VERSION ""

NS_ :

BS_:

BU_:
VAL_TABLE_ WarnLevel 2 "Level 2" 1 "Level 1" 0 "NoWarn" ;
VAL_TABLE_ LCAWarn 1 "CVW" 0 "BSD" ;
VAL_TABLE_ Status 1 "abnormal" 0 "Normal" ;
VAL_TABLE_ Lock 2 "RemoteControlLock" 1 "InteriorLock" 0 "UnLock" ;
VAL_TABLE_ Brake 1 "Brake" 0 " Normal" ;
VAL_TABLE_ Switch 1 "ON" 0 "OFF" ;
VAL_TABLE_ Gear 3 "D" 2 "N" 1 "R" 0 "P" ;

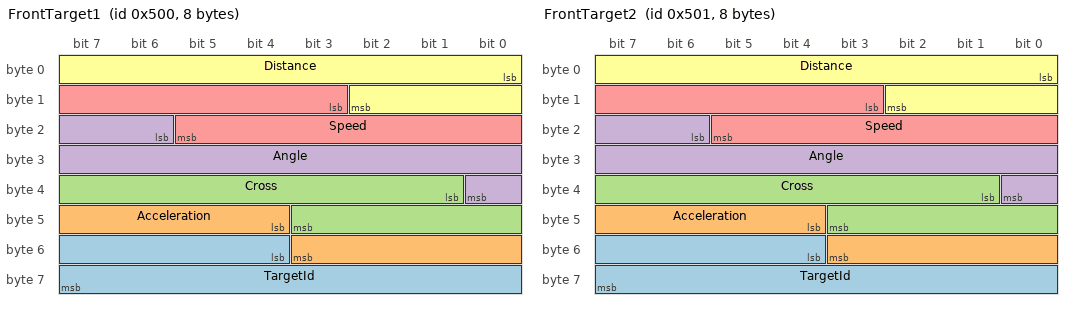
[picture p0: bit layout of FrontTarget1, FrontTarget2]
BO_ 1280 FrontTarget1: 8 Vector__XXX
 SG_ TargetId : 52|12@1+ (1,0) [0|0] "" Vector__XXX
 SG_ Acceleration : 44|8@1- (0.1,0) [0|0] "m/s^2" Vector__XXX
 SG_ Cross : 33|11@1- (0.1,0) [0|0] "m" Vector__XXX
 SG_ Angle : 22|11@1- (0.1,0) [0|0] "deg" Vector__XXX
 SG_ Speed : 11|11@1- (0.1,0) [0|0] "m/s" Vector__XXX
 SG_ Distance : 0|11@1+ (0.1,0) [0|0] "m" Vector__XXX

BO_ 1281 FrontTarget2: 8 Vector__XXX
 SG_ TargetId : 52|12@1+ (1,0) [0|0] "" Vector__XXX
 SG_ Acceleration : 44|8@1- (0.1,0) [0|0] "m/s^2" Vector__XXX
 SG_ Cross : 33|11@1- (0.1,0) [0|0] "m" Vector__XXX
 SG_ Angle : 22|11@1- (0.1,0) [0|0] "deg" Vector__XXX
 SG_ Speed : 11|11@1- (0.1,0) [0|0] "m/s" Vector__XXX
 SG_ Distance : 0|11@1+ (0.1,0) [0|0] "m" Vector__XXX

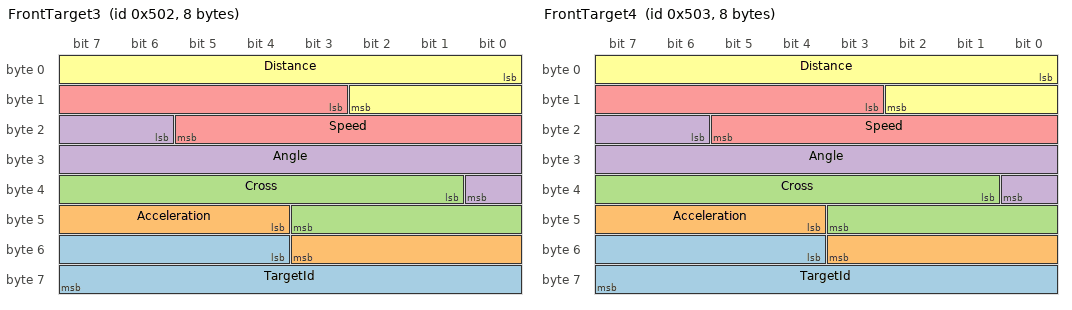
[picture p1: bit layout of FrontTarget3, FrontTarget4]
BO_ 1282 FrontTarget3: 8 Vector__XXX
 SG_ TargetId : 52|12@1+ (1,0) [0|0] "" Vector__XXX
 SG_ Acceleration : 44|8@1- (0.1,0) [0|0] "m/s^2" Vector__XXX
 SG_ Cross : 33|11@1- (0.1,0) [0|0] "m" Vector__XXX
 SG_ Angle : 22|11@1- (0.1,0) [0|0] "deg" Vector__XXX
 SG_ Speed : 11|11@1- (0.1,0) [0|0] "m/s" Vector__XXX
 SG_ Distance : 0|11@1+ (0.1,0) [0|0] "m" Vector__XXX

BO_ 1283 FrontTarget4: 8 Vector__XXX
 SG_ TargetId : 52|12@1+ (1,0) [0|0] "" Vector__XXX
 SG_ Acceleration : 44|8@1- (0.1,0) [0|0] "m/s^2" Vector__XXX
 SG_ Cross : 33|11@1- (0.1,0) [0|0] "m" Vector__XXX
 SG_ Angle : 22|11@1- (0.1,0) [0|0] "deg" Vector__XXX
 SG_ Speed : 11|11@1- (0.1,0) [0|0] "m/s" Vector__XXX
 SG_ Distance : 0|11@1+ (0.1,0) [0|0] "m" Vector__XXX

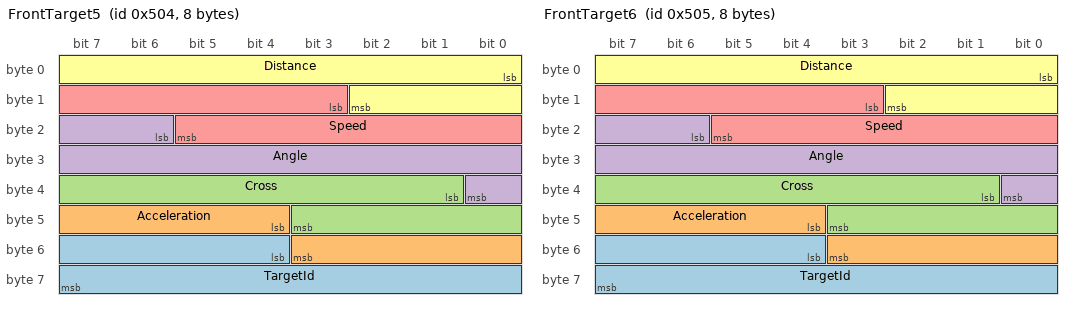
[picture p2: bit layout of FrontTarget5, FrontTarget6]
BO_ 1284 FrontTarget5: 8 Vector__XXX
 SG_ TargetId : 52|12@1+ (1,0) [0|0] "" Vector__XXX
 SG_ Acceleration : 44|8@1- (0.1,0) [0|0] "m/s^2" Vector__XXX
 SG_ Cross : 33|11@1- (0.1,0) [0|0] "m" Vector__XXX
 SG_ Angle : 22|11@1- (0.1,0) [0|0] "deg" Vector__XXX
 SG_ Speed : 11|11@1- (0.1,0) [0|0] "m/s" Vector__XXX
 SG_ Distance : 0|11@1+ (0.1,0) [0|0] "m" Vector__XXX

BO_ 1285 FrontTarget6: 8 Vector__XXX
 SG_ TargetId : 52|12@1+ (1,0) [0|0] "" Vector__XXX
 SG_ Acceleration : 44|8@1- (0.1,0) [0|0] "m/s^2" Vector__XXX
 SG_ Cross : 33|11@1- (0.1,0) [0|0] "m" Vector__XXX
 SG_ Angle : 22|11@1- (0.1,0) [0|0] "deg" Vector__XXX
 SG_ Speed : 11|11@1- (0.1,0) [0|0] "m/s" Vector__XXX
 SG_ Distance : 0|11@1+ (0.1,0) [0|0] "m" Vector__XXX

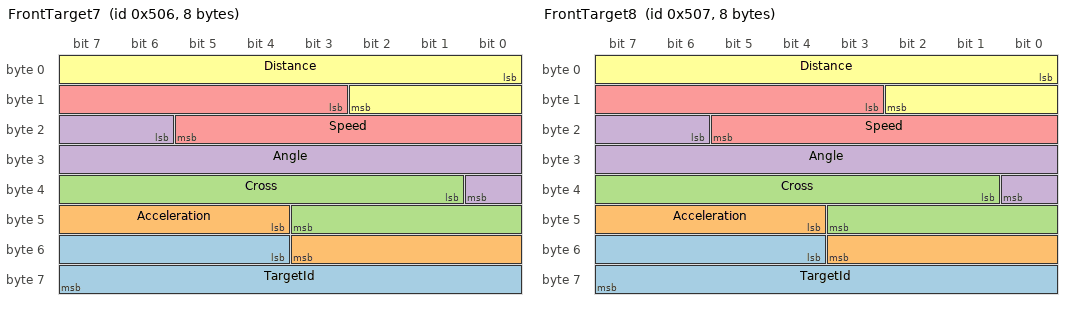
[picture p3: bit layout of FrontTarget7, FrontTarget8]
BO_ 1286 FrontTarget7: 8 Vector__XXX
 SG_ TargetId : 52|12@1+ (1,0) [0|0] "" Vector__XXX
 SG_ Acceleration : 44|8@1- (0.1,0) [0|0] "m/s^2" Vector__XXX
 SG_ Cross : 33|11@1- (0.1,0) [0|0] "m" Vector__XXX
 SG_ Angle : 22|11@1- (0.1,0) [0|0] "deg" Vector__XXX
 SG_ Speed : 11|11@1- (0.1,0) [0|0] "m/s" Vector__XXX
 SG_ Distance : 0|11@1+ (0.1,0) [0|0] "m" Vector__XXX

BO_ 1287 FrontTarget8: 8 Vector__XXX
 SG_ TargetId : 52|12@1+ (1,0) [0|0] "" Vector__XXX
 SG_ Acceleration : 44|8@1- (0.1,0) [0|0] "m/s^2" Vector__XXX
 SG_ Cross : 33|11@1- (0.1,0) [0|0] "m" Vector__XXX
 SG_ Angle : 22|11@1- (0.1,0) [0|0] "deg" Vector__XXX
 SG_ Speed : 11|11@1- (0.1,0) [0|0] "m/s" Vector__XXX
 SG_ Distance : 0|11@1+ (0.1,0) [0|0] "m" Vector__XXX

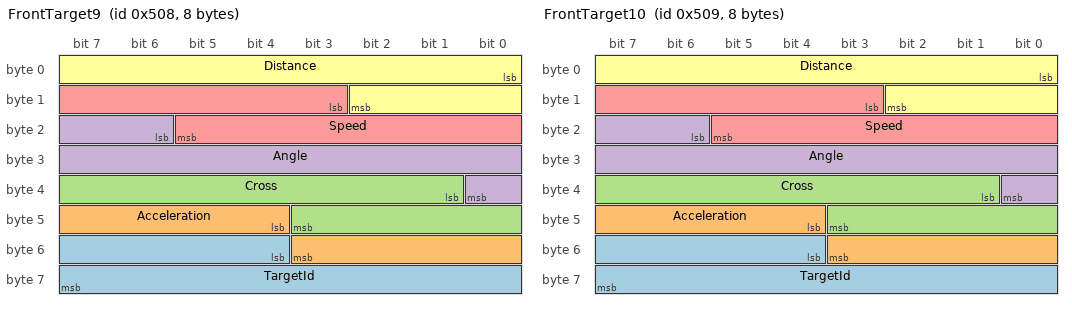
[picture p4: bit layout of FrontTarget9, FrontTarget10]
BO_ 1288 FrontTarget9: 8 Vector__XXX
 SG_ TargetId : 52|12@1+ (1,0) [0|0] "" Vector__XXX
 SG_ Acceleration : 44|8@1- (0.1,0) [0|0] "m/s^2" Vector__XXX
 SG_ Cross : 33|11@1- (0.1,0) [0|0] "m" Vector__XXX
 SG_ Angle : 22|11@1- (0.1,0) [0|0] "deg" Vector__XXX
 SG_ Speed : 11|11@1- (0.1,0) [0|0] "m/s" Vector__XXX
 SG_ Distance : 0|11@1+ (0.1,0) [0|0] "m" Vector__XXX

BO_ 1289 FrontTarget10: 8 Vector__XXX
 SG_ TargetId : 52|12@1+ (1,0) [0|0] "" Vector__XXX
 SG_ Acceleration : 44|8@1- (0.1,0) [0|0] "m/s^2" Vector__XXX
 SG_ Cross : 33|11@1- (0.1,0) [0|0] "m" Vector__XXX
 SG_ Angle : 22|11@1- (0.1,0) [0|0] "deg" Vector__XXX
 SG_ Speed : 11|11@1- (0.1,0) [0|0] "m/s" Vector__XXX
 SG_ Distance : 0|11@1+ (0.1,0) [0|0] "m" Vector__XXX

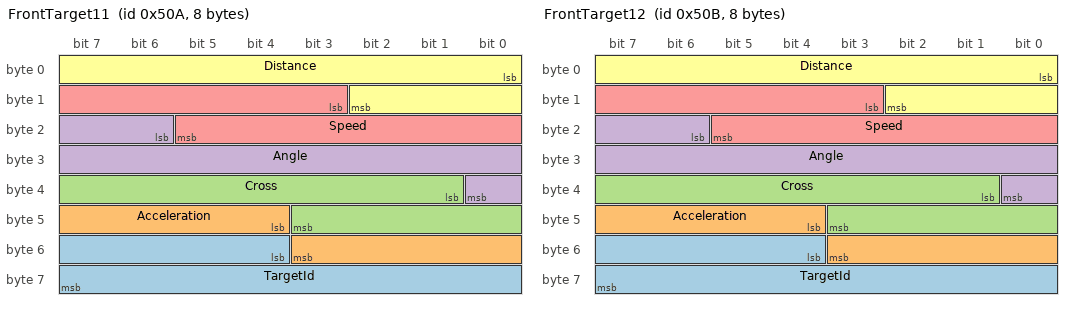
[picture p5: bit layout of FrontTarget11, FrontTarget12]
BO_ 1290 FrontTarget11: 8 Vector__XXX
 SG_ TargetId : 52|12@1+ (1,0) [0|0] "" Vector__XXX
 SG_ Acceleration : 44|8@1- (0.1,0) [0|0] "m/s^2" Vector__XXX
 SG_ Cross : 33|11@1- (0.1,0) [0|0] "m" Vector__XXX
 SG_ Angle : 22|11@1- (0.1,0) [0|0] "deg" Vector__XXX
 SG_ Speed : 11|11@1- (0.1,0) [0|0] "m/s" Vector__XXX
 SG_ Distance : 0|11@1+ (0.1,0) [0|0] "m" Vector__XXX

BO_ 1291 FrontTarget12: 8 Vector__XXX
 SG_ TargetId : 52|12@1+ (1,0) [0|0] "" Vector__XXX
 SG_ Acceleration : 44|8@1- (0.1,0) [0|0] "m/s^2" Vector__XXX
 SG_ Cross : 33|11@1- (0.1,0) [0|0] "m" Vector__XXX
 SG_ Angle : 22|11@1- (0.1,0) [0|0] "deg" Vector__XXX
 SG_ Speed : 11|11@1- (0.1,0) [0|0] "m/s" Vector__XXX
 SG_ Distance : 0|11@1+ (0.1,0) [0|0] "m" Vector__XXX

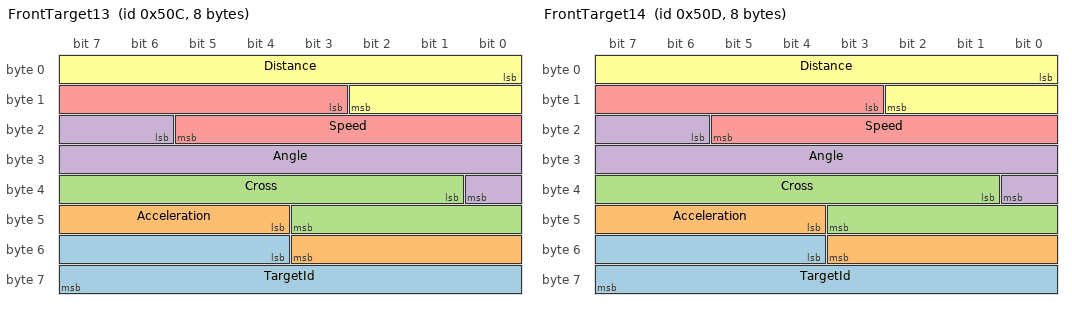
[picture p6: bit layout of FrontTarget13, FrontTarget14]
BO_ 1292 FrontTarget13: 8 Vector__XXX
 SG_ TargetId : 52|12@1+ (1,0) [0|0] "" Vector__XXX
 SG_ Acceleration : 44|8@1- (0.1,0) [0|0] "m/s^2" Vector__XXX
 SG_ Cross : 33|11@1- (0.1,0) [0|0] "m" Vector__XXX
 SG_ Angle : 22|11@1- (0.1,0) [0|0] "deg" Vector__XXX
 SG_ Speed : 11|11@1- (0.1,0) [0|0] "m/s" Vector__XXX
 SG_ Distance : 0|11@1+ (0.1,0) [0|0] "m" Vector__XXX

BO_ 1293 FrontTarget14: 8 Vector__XXX
 SG_ TargetId : 52|12@1+ (1,0) [0|0] "" Vector__XXX
 SG_ Acceleration : 44|8@1- (0.1,0) [0|0] "m/s^2" Vector__XXX
 SG_ Cross : 33|11@1- (0.1,0) [0|0] "m" Vector__XXX
 SG_ Angle : 22|11@1- (0.1,0) [0|0] "deg" Vector__XXX
 SG_ Speed : 11|11@1- (0.1,0) [0|0] "m/s" Vector__XXX
 SG_ Distance : 0|11@1+ (0.1,0) [0|0] "m" Vector__XXX

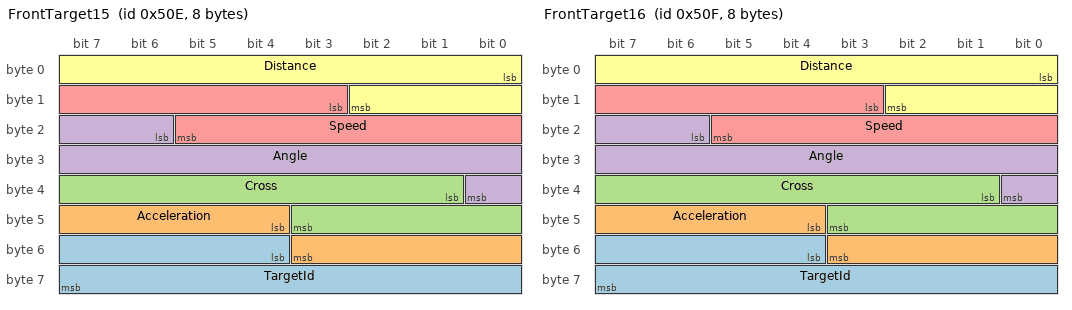
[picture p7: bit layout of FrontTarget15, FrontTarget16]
BO_ 1294 FrontTarget15: 8 Vector__XXX
 SG_ TargetId : 52|12@1+ (1,0) [0|0] "" Vector__XXX
 SG_ Acceleration : 44|8@1- (0.1,0) [0|0] "m/s^2" Vector__XXX
 SG_ Cross : 33|11@1- (0.1,0) [0|0] "m" Vector__XXX
 SG_ Angle : 22|11@1- (0.1,0) [0|0] "deg" Vector__XXX
 SG_ Speed : 11|11@1- (0.1,0) [0|0] "m/s" Vector__XXX
 SG_ Distance : 0|11@1+ (0.1,0) [0|0] "m" Vector__XXX

BO_ 1295 FrontTarget16: 8 Vector__XXX
 SG_ TargetId : 52|12@1+ (1,0) [0|0] "" Vector__XXX
 SG_ Acceleration : 44|8@1- (0.1,0) [0|0] "m/s^2" Vector__XXX
 SG_ Cross : 33|11@1- (0.1,0) [0|0] "m" Vector__XXX
 SG_ Angle : 22|11@1- (0.1,0) [0|0] "deg" Vector__XXX
 SG_ Speed : 11|11@1- (0.1,0) [0|0] "m/s" Vector__XXX
 SG_ Distance : 0|11@1+ (0.1,0) [0|0] "m" Vector__XXX

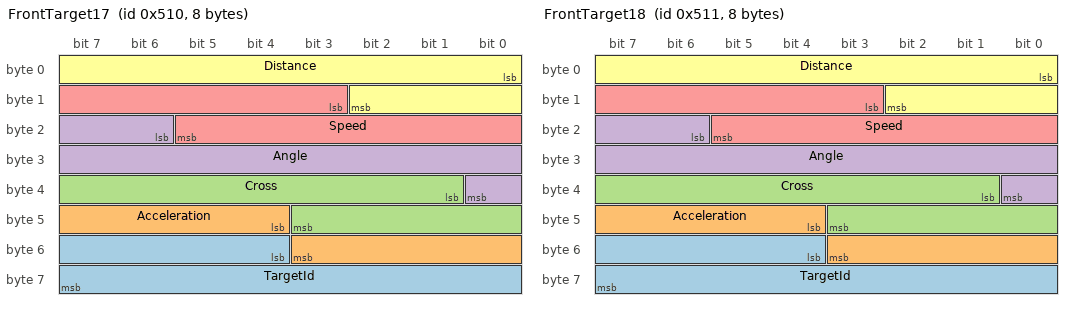
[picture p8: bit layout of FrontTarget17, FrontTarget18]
BO_ 1296 FrontTarget17: 8 Vector__XXX
 SG_ TargetId : 52|12@1+ (1,0) [0|0] "" Vector__XXX
 SG_ Acceleration : 44|8@1- (0.1,0) [0|0] "m/s^2" Vector__XXX
 SG_ Cross : 33|11@1- (0.1,0) [0|0] "m" Vector__XXX
 SG_ Angle : 22|11@1- (0.1,0) [0|0] "deg" Vector__XXX
 SG_ Speed : 11|11@1- (0.1,0) [0|0] "m/s" Vector__XXX
 SG_ Distance : 0|11@1+ (0.1,0) [0|0] "m" Vector__XXX

BO_ 1297 FrontTarget18: 8 Vector__XXX
 SG_ TargetId : 52|12@1+ (1,0) [0|0] "" Vector__XXX
 SG_ Acceleration : 44|8@1- (0.1,0) [0|0] "m/s^2" Vector__XXX
 SG_ Cross : 33|11@1- (0.1,0) [0|0] "m" Vector__XXX
 SG_ Angle : 22|11@1- (0.1,0) [0|0] "deg" Vector__XXX
 SG_ Speed : 11|11@1- (0.1,0) [0|0] "m/s" Vector__XXX
 SG_ Distance : 0|11@1+ (0.1,0) [0|0] "m" Vector__XXX

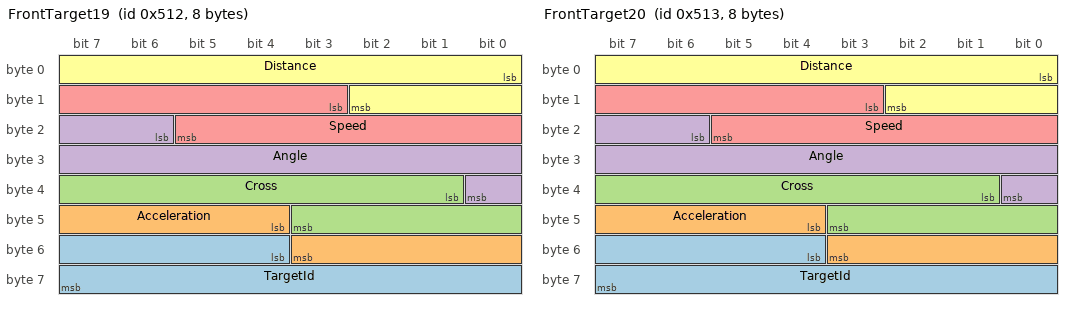
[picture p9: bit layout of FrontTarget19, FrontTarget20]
BO_ 1298 FrontTarget19: 8 Vector__XXX
 SG_ TargetId : 52|12@1+ (1,0) [0|0] "" Vector__XXX
 SG_ Acceleration : 44|8@1- (0.1,0) [0|0] "m/s^2" Vector__XXX
 SG_ Cross : 33|11@1- (0.1,0) [0|0] "m" Vector__XXX
 SG_ Angle : 22|11@1- (0.1,0) [0|0] "deg" Vector__XXX
 SG_ Speed : 11|11@1- (0.1,0) [0|0] "m/s" Vector__XXX
 SG_ Distance : 0|11@1+ (0.1,0) [0|0] "m" Vector__XXX

BO_ 1299 FrontTarget20: 8 Vector__XXX
 SG_ TargetId : 52|12@1+ (1,0) [0|0] "" Vector__XXX
 SG_ Acceleration : 44|8@1- (0.1,0) [0|0] "m/s^2" Vector__XXX
 SG_ Cross : 33|11@1- (0.1,0) [0|0] "m" Vector__XXX
 SG_ Angle : 22|11@1- (0.1,0) [0|0] "deg" Vector__XXX
 SG_ Speed : 11|11@1- (0.1,0) [0|0] "m/s" Vector__XXX
 SG_ Distance : 0|11@1+ (0.1,0) [0|0] "m" Vector__XXX

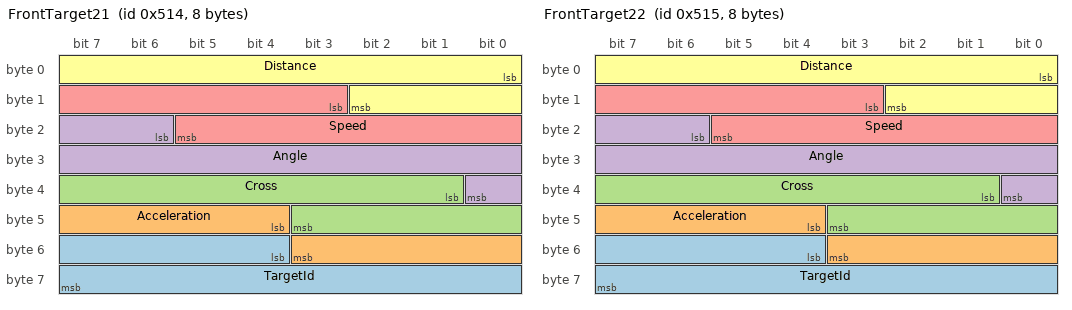
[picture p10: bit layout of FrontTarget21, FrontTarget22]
BO_ 1300 FrontTarget21: 8 Vector__XXX
 SG_ TargetId : 52|12@1+ (1,0) [0|0] "" Vector__XXX
 SG_ Acceleration : 44|8@1- (0.1,0) [0|0] "m/s^2" Vector__XXX
 SG_ Cross : 33|11@1- (0.1,0) [0|0] "m" Vector__XXX
 SG_ Angle : 22|11@1- (0.1,0) [0|0] "deg" Vector__XXX
 SG_ Speed : 11|11@1- (0.1,0) [0|0] "m/s" Vector__XXX
 SG_ Distance : 0|11@1+ (0.1,0) [0|0] "m" Vector__XXX

BO_ 1301 FrontTarget22: 8 Vector__XXX
 SG_ TargetId : 52|12@1+ (1,0) [0|0] "" Vector__XXX
 SG_ Acceleration : 44|8@1- (0.1,0) [0|0] "m/s^2" Vector__XXX
 SG_ Cross : 33|11@1- (0.1,0) [0|0] "m" Vector__XXX
 SG_ Angle : 22|11@1- (0.1,0) [0|0] "deg" Vector__XXX
 SG_ Speed : 11|11@1- (0.1,0) [0|0] "m/s" Vector__XXX
 SG_ Distance : 0|11@1+ (0.1,0) [0|0] "m" Vector__XXX

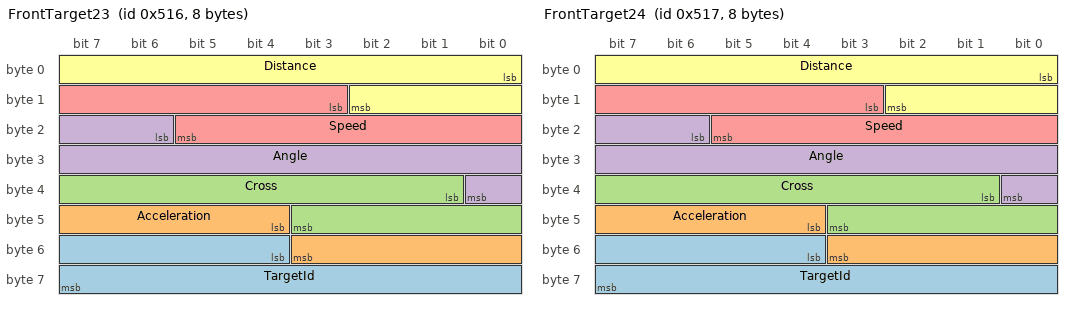
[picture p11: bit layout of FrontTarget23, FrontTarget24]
BO_ 1302 FrontTarget23: 8 Vector__XXX
 SG_ TargetId : 52|12@1+ (1,0) [0|0] "" Vector__XXX
 SG_ Acceleration : 44|8@1- (0.1,0) [0|0] "m/s^2" Vector__XXX
 SG_ Cross : 33|11@1- (0.1,0) [0|0] "m" Vector__XXX
 SG_ Angle : 22|11@1- (0.1,0) [0|0] "deg" Vector__XXX
 SG_ Speed : 11|11@1- (0.1,0) [0|0] "m/s" Vector__XXX
 SG_ Distance : 0|11@1+ (0.1,0) [0|0] "m" Vector__XXX

BO_ 1303 FrontTarget24: 8 Vector__XXX
 SG_ TargetId : 52|12@1+ (1,0) [0|0] "" Vector__XXX
 SG_ Acceleration : 44|8@1- (0.1,0) [0|0] "m/s^2" Vector__XXX
 SG_ Cross : 33|11@1- (0.1,0) [0|0] "m" Vector__XXX
 SG_ Angle : 22|11@1- (0.1,0) [0|0] "deg" Vector__XXX
 SG_ Speed : 11|11@1- (0.1,0) [0|0] "m/s" Vector__XXX
 SG_ Distance : 0|11@1+ (0.1,0) [0|0] "m" Vector__XXX

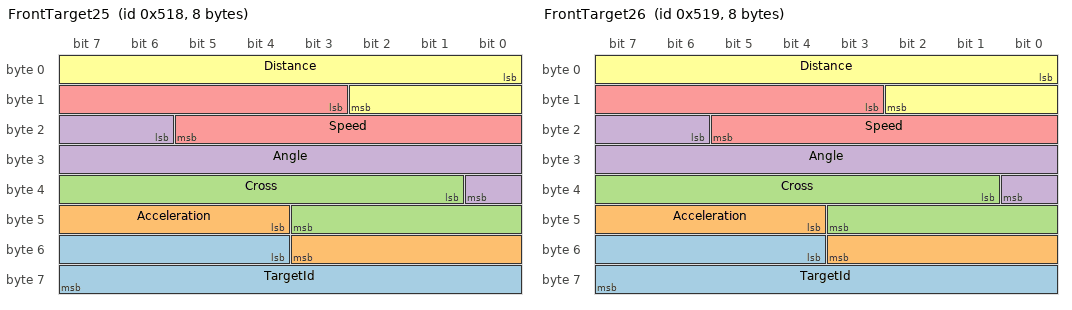
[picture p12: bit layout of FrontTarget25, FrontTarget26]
BO_ 1304 FrontTarget25: 8 Vector__XXX
 SG_ TargetId : 52|12@1+ (1,0) [0|0] "" Vector__XXX
 SG_ Acceleration : 44|8@1- (0.1,0) [0|0] "m/s^2" Vector__XXX
 SG_ Cross : 33|11@1- (0.1,0) [0|0] "m" Vector__XXX
 SG_ Angle : 22|11@1- (0.1,0) [0|0] "deg" Vector__XXX
 SG_ Speed : 11|11@1- (0.1,0) [0|0] "m/s" Vector__XXX
 SG_ Distance : 0|11@1+ (0.1,0) [0|0] "m" Vector__XXX

BO_ 1305 FrontTarget26: 8 Vector__XXX
 SG_ TargetId : 52|12@1+ (1,0) [0|0] "" Vector__XXX
 SG_ Acceleration : 44|8@1- (0.1,0) [0|0] "m/s^2" Vector__XXX
 SG_ Cross : 33|11@1- (0.1,0) [0|0] "m" Vector__XXX
 SG_ Angle : 22|11@1- (0.1,0) [0|0] "deg" Vector__XXX
 SG_ Speed : 11|11@1- (0.1,0) [0|0] "m/s" Vector__XXX
 SG_ Distance : 0|11@1+ (0.1,0) [0|0] "m" Vector__XXX

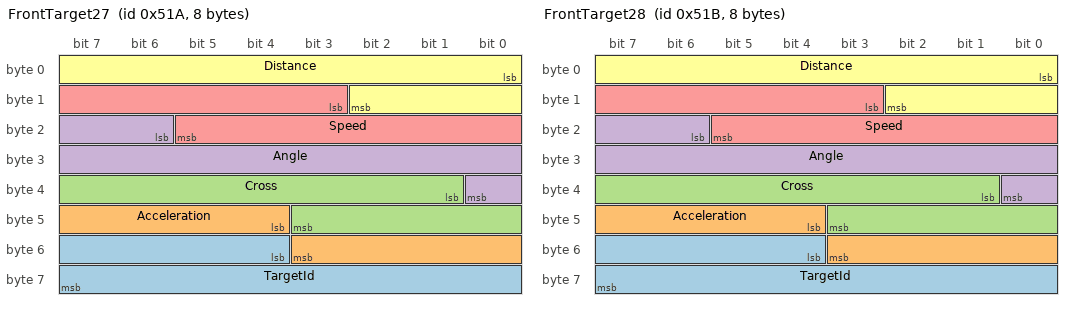
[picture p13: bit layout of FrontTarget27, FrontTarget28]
BO_ 1306 FrontTarget27: 8 Vector__XXX
 SG_ TargetId : 52|12@1+ (1,0) [0|0] "" Vector__XXX
 SG_ Acceleration : 44|8@1- (0.1,0) [0|0] "m/s^2" Vector__XXX
 SG_ Cross : 33|11@1- (0.1,0) [0|0] "m" Vector__XXX
 SG_ Angle : 22|11@1- (0.1,0) [0|0] "deg" Vector__XXX
 SG_ Speed : 11|11@1- (0.1,0) [0|0] "m/s" Vector__XXX
 SG_ Distance : 0|11@1+ (0.1,0) [0|0] "m" Vector__XXX

BO_ 1307 FrontTarget28: 8 Vector__XXX
 SG_ TargetId : 52|12@1+ (1,0) [0|0] "" Vector__XXX
 SG_ Acceleration : 44|8@1- (0.1,0) [0|0] "m/s^2" Vector__XXX
 SG_ Cross : 33|11@1- (0.1,0) [0|0] "m" Vector__XXX
 SG_ Angle : 22|11@1- (0.1,0) [0|0] "deg" Vector__XXX
 SG_ Speed : 11|11@1- (0.1,0) [0|0] "m/s" Vector__XXX
 SG_ Distance : 0|11@1+ (0.1,0) [0|0] "m" Vector__XXX

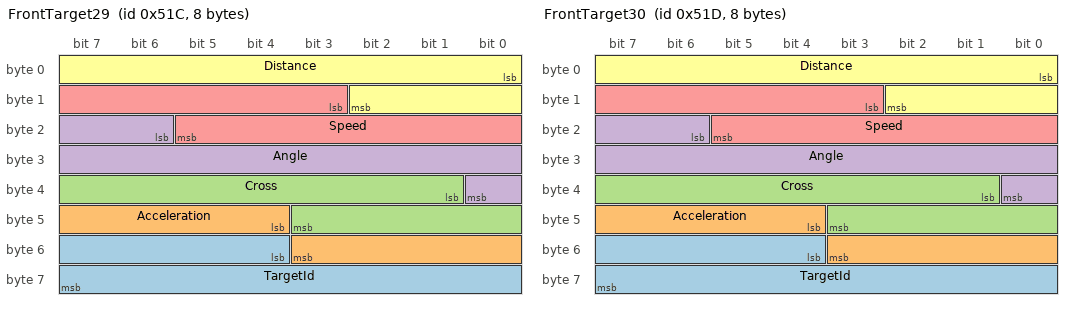
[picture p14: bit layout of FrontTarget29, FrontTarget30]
BO_ 1308 FrontTarget29: 8 Vector__XXX
 SG_ TargetId : 52|12@1+ (1,0) [0|0] "" Vector__XXX
 SG_ Acceleration : 44|8@1- (0.1,0) [0|0] "m/s^2" Vector__XXX
 SG_ Cross : 33|11@1- (0.1,0) [0|0] "m" Vector__XXX
 SG_ Angle : 22|11@1- (0.1,0) [0|0] "deg" Vector__XXX
 SG_ Speed : 11|11@1- (0.1,0) [0|0] "m/s" Vector__XXX
 SG_ Distance : 0|11@1+ (0.1,0) [0|0] "m" Vector__XXX

BO_ 1309 FrontTarget30: 8 Vector__XXX
 SG_ TargetId : 52|12@1+ (1,0) [0|0] "" Vector__XXX
 SG_ Acceleration : 44|8@1- (0.1,0) [0|0] "m/s^2" Vector__XXX
 SG_ Cross : 33|11@1- (0.1,0) [0|0] "m" Vector__XXX
 SG_ Angle : 22|11@1- (0.1,0) [0|0] "deg" Vector__XXX
 SG_ Speed : 11|11@1- (0.1,0) [0|0] "m/s" Vector__XXX
 SG_ Distance : 0|11@1+ (0.1,0) [0|0] "m" Vector__XXX

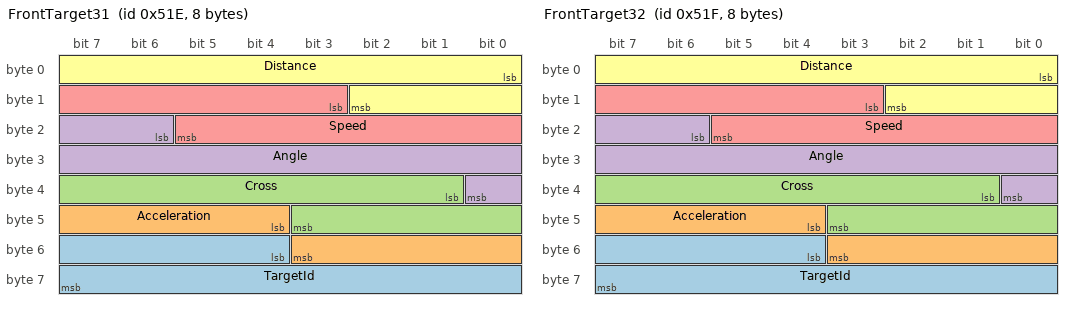
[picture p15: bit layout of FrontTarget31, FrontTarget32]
BO_ 1310 FrontTarget31: 8 Vector__XXX
 SG_ TargetId : 52|12@1+ (1,0) [0|0] "" Vector__XXX
 SG_ Acceleration : 44|8@1- (0.1,0) [0|0] "m/s^2" Vector__XXX
 SG_ Cross : 33|11@1- (0.1,0) [0|0] "m" Vector__XXX
 SG_ Angle : 22|11@1- (0.1,0) [0|0] "deg" Vector__XXX
 SG_ Speed : 11|11@1- (0.1,0) [0|0] "m/s" Vector__XXX
 SG_ Distance : 0|11@1+ (0.1,0) [0|0] "m" Vector__XXX

BO_ 1311 FrontTarget32: 8 Vector__XXX
 SG_ TargetId : 52|12@1+ (1,0) [0|0] "" Vector__XXX
 SG_ Acceleration : 44|8@1- (0.1,0) [0|0] "m/s^2" Vector__XXX
 SG_ Cross : 33|11@1- (0.1,0) [0|0] "m" Vector__XXX
 SG_ Angle : 22|11@1- (0.1,0) [0|0] "deg" Vector__XXX
 SG_ Speed : 11|11@1- (0.1,0) [0|0] "m/s" Vector__XXX
 SG_ Distance : 0|11@1+ (0.1,0) [0|0] "m" Vector__XXX

BO_ 1312 FrontRadarCnt: 8 Vector__XXX
 SG_ TargetCnt : 0|8@1+ (1,0) [0|0] "" Vector__XXX

BA_DEF_ BO_  "GenMsgCycleTime" INT 0 0;
BA_DEF_DEF_  "GenMsgCycleTime" 0;
BA_ "GenMsgCycleTime" BO_ 1280 60;
BA_ "GenMsgCycleTime" BO_ 1281 60;
BA_ "GenMsgCycleTime" BO_ 1282 60;
BA_ "GenMsgCycleTime" BO_ 1283 60;
BA_ "GenMsgCycleTime" BO_ 1284 60;
BA_ "GenMsgCycleTime" BO_ 1285 60;
BA_ "GenMsgCycleTime" BO_ 1286 60;
BA_ "GenMsgCycleTime" BO_ 1287 60;
BA_ "GenMsgCycleTime" BO_ 1288 60;
BA_ "GenMsgCycleTime" BO_ 1289 60;
BA_ "GenMsgCycleTime" BO_ 1290 60;
BA_ "GenMsgCycleTime" BO_ 1291 60;
BA_ "GenMsgCycleTime" BO_ 1292 60;
BA_ "GenMsgCycleTime" BO_ 1293 60;
BA_ "GenMsgCycleTime" BO_ 1294 60;
BA_ "GenMsgCycleTime" BO_ 1295 60;
BA_ "GenMsgCycleTime" BO_ 1296 60;
BA_ "GenMsgCycleTime" BO_ 1297 60;
BA_ "GenMsgCycleTime" BO_ 1298 60;
BA_ "GenMsgCycleTime" BO_ 1299 60;
BA_ "GenMsgCycleTime" BO_ 1300 60;
BA_ "GenMsgCycleTime" BO_ 1301 60;
BA_ "GenMsgCycleTime" BO_ 1302 60;
BA_ "GenMsgCycleTime" BO_ 1303 60;
BA_ "GenMsgCycleTime" BO_ 1304 60;
BA_ "GenMsgCycleTime" BO_ 1305 60;
BA_ "GenMsgCycleTime" BO_ 1306 60;
BA_ "GenMsgCycleTime" BO_ 1307 60;
BA_ "GenMsgCycleTime" BO_ 1308 60;
BA_ "GenMsgCycleTime" BO_ 1309 60;
BA_ "GenMsgCycleTime" BO_ 1310 60;
BA_ "GenMsgCycleTime" BO_ 1311 60;
BA_ "GenMsgCycleTime" BO_ 1312 60;
